# MCU_ECC_AGGR0_ECC_AGGR register map
Vendor: Texas Instruments
Peripheral module from a debugger description file (folder am243x).
Registers are 32-bit, access not given, reset 0x0 unless marked. A register's access mark holds for its fields unless they carry their own. Offsets are as the file gives them; lines under a group give offsets from that group; [hi:lo] are bit positions; {n}, {i} and the like mark numbered series; 'fields as' and 'values as' point back to an identical list; <NAME> marks a mode.

## MCU_ECC_AGGR0_ECC_AGGR
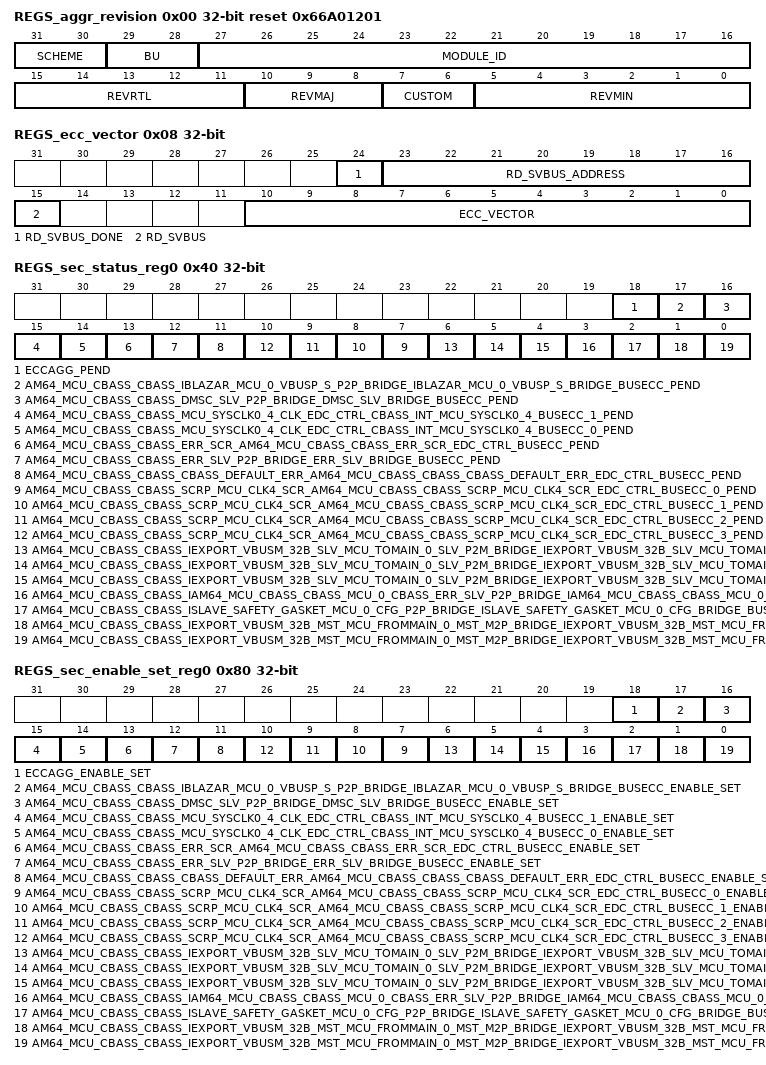
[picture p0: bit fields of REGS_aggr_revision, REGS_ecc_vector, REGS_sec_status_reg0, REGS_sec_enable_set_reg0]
0x00 REGS_aggr_revision ro reset 0x66A01201 — Revision parameters
  [31:30] SCHEME
  [29:28] BU
  [27:16] MODULE_ID
  [15:11] REVRTL — RTL version
  [10:8] REVMAJ — Major version
  [7:6] CUSTOM — Custom version
  [5:0] REVMIN — Minor version
0x08 REGS_ecc_vector — ECC Vector Register
  [24] RD_SVBUS_DONE — Status to indicate if read on serial VBUS is complete, write of any value will clear this bit. (access R/W1TC)
  [23:16] RD_SVBUS_ADDRESS rw — Read address
  [15] RD_SVBUS — Write 1 to trigger a read on the serial VBUS (access R/W1TS)
  [10:0] ECC_VECTOR rw — Value written to select the corresponding ECC RAM for control or status
0x0C REGS_misc_status ro reset 0x13 — Misc Status
  [10:0] NUM_RAMS — Indicates the number of RAMS serviced by the ECC aggregator
0x10 REGS_reserved_svbus rw — Reference other documents that contain the ECC RAM wrapper and EDC controller serial vbus register sets.
  [31:0] DATA — Serial VBUS register data
0x3C REGS_sec_eoi_reg — EOI Register
  [0] EOI_WR — EOI Register (access R/W1TS)
0x40 REGS_sec_status_reg0 — Interrupt Status Register 0
  [18] ECCAGG_PEND — Interrupt Pending Status for eccagg_pend (access R/W1TS)
  [17] AM64_MCU_CBASS_CBASS_IBLAZAR_MCU_0_VBUSP_S_P2P_BRIDGE_IBLAZAR_MCU_0_VBUSP_S_BRIDGE_BUSECC_PEND — Interrupt Pending Status for am64_mcu_cbass_cbass_Iblazar_mcu_0_vbusp_s_p2p_bridge_Iblazar_mcu_0_vbusp_s_bridge_busecc_pend (access R/W1TS)
  [16] AM64_MCU_CBASS_CBASS_DMSC_SLV_P2P_BRIDGE_DMSC_SLV_BRIDGE_BUSECC_PEND — Interrupt Pending Status for am64_mcu_cbass_cbass_dmsc_slv_p2p_bridge_dmsc_slv_bridge_busecc_pend (access R/W1TS)
  [15] AM64_MCU_CBASS_CBASS_MCU_SYSCLK0_4_CLK_EDC_CTRL_CBASS_INT_MCU_SYSCLK0_4_BUSECC_1_PEND — Interrupt Pending Status for am64_mcu_cbass_cbass_MCU_SYSCLK0_4_clk_edc_ctrl_cbass_int_MCU_SYSCLK0_4_busecc_1_pend (access R/W1TS)
  [14] AM64_MCU_CBASS_CBASS_MCU_SYSCLK0_4_CLK_EDC_CTRL_CBASS_INT_MCU_SYSCLK0_4_BUSECC_0_PEND — Interrupt Pending Status for am64_mcu_cbass_cbass_MCU_SYSCLK0_4_clk_edc_ctrl_cbass_int_MCU_SYSCLK0_4_busecc_0_pend (access R/W1TS)
  [13] AM64_MCU_CBASS_CBASS_ERR_SCR_AM64_MCU_CBASS_CBASS_ERR_SCR_EDC_CTRL_BUSECC_PEND — Interrupt Pending Status for am64_mcu_cbass_cbass_err_scr_am64_mcu_cbass_cbass_err_scr_edc_ctrl_busecc_pend (access R/W1TS)
  [12] AM64_MCU_CBASS_CBASS_ERR_SLV_P2P_BRIDGE_ERR_SLV_BRIDGE_BUSECC_PEND — Interrupt Pending Status for am64_mcu_cbass_cbass_err_slv_p2p_bridge_err_slv_bridge_busecc_pend (access R/W1TS)
  [11] AM64_MCU_CBASS_CBASS_CBASS_DEFAULT_ERR_AM64_MCU_CBASS_CBASS_CBASS_DEFAULT_ERR_EDC_CTRL_BUSECC_PEND — Interrupt Pending Status for am64_mcu_cbass_cbass_cbass_default_err_am64_mcu_cbass_cbass_cbass_default_err_edc_ctrl_busecc_pend (access R/W1TS)
  [n+7] AM64_MCU_CBASS_CBASS_SCRP_MCU_CLK4_SCR_AM64_MCU_CBASS_CBASS_SCRP_MCU_CLK4_SCR_EDC_CTRL_BUSECC_{n}_PEND (n=0..3) — Interrupt Pending Status for am64_mcu_cbass_cbass_scrp_mcu_clk4_scr_am64_mcu_cbass_cbass_scrp_mcu_clk4_scr_edc_ctrl_busecc_{n}_pend (access R/W1TS)
  [6] AM64_MCU_CBASS_CBASS_IEXPORT_VBUSM_32B_SLV_MCU_TOMAIN_0_SLV_P2M_BRIDGE_IEXPORT_VBUSM_32B_SLV_MCU_TOMAIN_0_SLV_BRIDGE_REASSEMBLY_BUSECC_PEND — Interrupt Pending Status for am64_mcu_cbass_cbass_Iexport_vbusm_32b_slv_mcu_tomain_0_slv_p2m_bridge_Iexport_vbusm_32b_slv_mcu_tomain_0_slv_bridge_reassembly_busecc_pend (access R/W1TS)
  [5] AM64_MCU_CBASS_CBASS_IEXPORT_VBUSM_32B_SLV_MCU_TOMAIN_0_SLV_P2M_BRIDGE_IEXPORT_VBUSM_32B_SLV_MCU_TOMAIN_0_SLV_BRIDGE_DST_BUSECC_PEND — Interrupt Pending Status for am64_mcu_cbass_cbass_Iexport_vbusm_32b_slv_mcu_tomain_0_slv_p2m_bridge_Iexport_vbusm_32b_slv_mcu_tomain_0_slv_bridge_dst_busecc_pend (access R/W1TS)
  [4] AM64_MCU_CBASS_CBASS_IEXPORT_VBUSM_32B_SLV_MCU_TOMAIN_0_SLV_P2M_BRIDGE_IEXPORT_VBUSM_32B_SLV_MCU_TOMAIN_0_SLV_BRIDGE_SRC_BUSECC_PEND — Interrupt Pending Status for am64_mcu_cbass_cbass_Iexport_vbusm_32b_slv_mcu_tomain_0_slv_p2m_bridge_Iexport_vbusm_32b_slv_mcu_tomain_0_slv_bridge_src_busecc_pend (access R/W1TS)
  [3] AM64_MCU_CBASS_CBASS_IAM64_MCU_CBASS_CBASS_MCU_0_CBASS_ERR_SLV_P2P_BRIDGE_IAM64_MCU_CBASS_CBASS_MCU_0_CBASS_ERR_SLV_BRIDGE_BUSECC_PEND — Interrupt Pending Status for am64_mcu_cbass_cbass_Iam64_mcu_cbass_cbass_mcu_0_cbass_err_slv_p2p_bridge_Iam64_mcu_cbass_cbass_mcu_0_cbass_err_slv_bridge_busecc_pend (access R/W1TS)
  [2] AM64_MCU_CBASS_CBASS_ISLAVE_SAFETY_GASKET_MCU_0_CFG_P2P_BRIDGE_ISLAVE_SAFETY_GASKET_MCU_0_CFG_BRIDGE_BUSECC_PEND — Interrupt Pending Status for am64_mcu_cbass_cbass_Islave_safety_gasket_mcu_0_cfg_p2p_bridge_Islave_safety_gasket_mcu_0_cfg_bridge_busecc_pend (access R/W1TS)
  [1] AM64_MCU_CBASS_CBASS_IEXPORT_VBUSM_32B_MST_MCU_FROMMAIN_0_MST_M2P_BRIDGE_IEXPORT_VBUSM_32B_MST_MCU_FROMMAIN_0_MST_BRIDGE_DST_BUSECC_PEND — Interrupt Pending Status for am64_mcu_cbass_cbass_Iexport_vbusm_32b_mst_mcu_frommain_0_mst_m2p_bridge_Iexport_vbusm_32b_mst_mcu_frommain_0_mst_bridge_dst_busecc_pend (access R/W1TS)
  [0] AM64_MCU_CBASS_CBASS_IEXPORT_VBUSM_32B_MST_MCU_FROMMAIN_0_MST_M2P_BRIDGE_IEXPORT_VBUSM_32B_MST_MCU_FROMMAIN_0_MST_BRIDGE_SRC_BUSECC_PEND — Interrupt Pending Status for am64_mcu_cbass_cbass_Iexport_vbusm_32b_mst_mcu_frommain_0_mst_m2p_bridge_Iexport_vbusm_32b_mst_mcu_frommain_0_mst_bridge_src_busecc_pend (access R/W1TS)
0x80 REGS_sec_enable_set_reg0 — Interrupt Enable Set Register 0
  [18] ECCAGG_ENABLE_SET — Interrupt Enable Set Register for eccagg_pend (access R/W1TS)
  [17] AM64_MCU_CBASS_CBASS_IBLAZAR_MCU_0_VBUSP_S_P2P_BRIDGE_IBLAZAR_MCU_0_VBUSP_S_BRIDGE_BUSECC_ENABLE_SET — Interrupt Enable Set Register for am64_mcu_cbass_cbass_Iblazar_mcu_0_vbusp_s_p2p_bridge_Iblazar_mcu_0_vbusp_s_bridge_busecc_pend (access R/W1TS)
  [16] AM64_MCU_CBASS_CBASS_DMSC_SLV_P2P_BRIDGE_DMSC_SLV_BRIDGE_BUSECC_ENABLE_SET — Interrupt Enable Set Register for am64_mcu_cbass_cbass_dmsc_slv_p2p_bridge_dmsc_slv_bridge_busecc_pend (access R/W1TS)
  [15] AM64_MCU_CBASS_CBASS_MCU_SYSCLK0_4_CLK_EDC_CTRL_CBASS_INT_MCU_SYSCLK0_4_BUSECC_1_ENABLE_SET — Interrupt Enable Set Register for am64_mcu_cbass_cbass_MCU_SYSCLK0_4_clk_edc_ctrl_cbass_int_MCU_SYSCLK0_4_busecc_1_pend (access R/W1TS)
  [14] AM64_MCU_CBASS_CBASS_MCU_SYSCLK0_4_CLK_EDC_CTRL_CBASS_INT_MCU_SYSCLK0_4_BUSECC_0_ENABLE_SET — Interrupt Enable Set Register for am64_mcu_cbass_cbass_MCU_SYSCLK0_4_clk_edc_ctrl_cbass_int_MCU_SYSCLK0_4_busecc_0_pend (access R/W1TS)
  [13] AM64_MCU_CBASS_CBASS_ERR_SCR_AM64_MCU_CBASS_CBASS_ERR_SCR_EDC_CTRL_BUSECC_ENABLE_SET — Interrupt Enable Set Register for am64_mcu_cbass_cbass_err_scr_am64_mcu_cbass_cbass_err_scr_edc_ctrl_busecc_pend (access R/W1TS)
  [12] AM64_MCU_CBASS_CBASS_ERR_SLV_P2P_BRIDGE_ERR_SLV_BRIDGE_BUSECC_ENABLE_SET — Interrupt Enable Set Register for am64_mcu_cbass_cbass_err_slv_p2p_bridge_err_slv_bridge_busecc_pend (access R/W1TS)
  [11] AM64_MCU_CBASS_CBASS_CBASS_DEFAULT_ERR_AM64_MCU_CBASS_CBASS_CBASS_DEFAULT_ERR_EDC_CTRL_BUSECC_ENABLE_SET — Interrupt Enable Set Register for am64_mcu_cbass_cbass_cbass_default_err_am64_mcu_cbass_cbass_cbass_default_err_edc_ctrl_busecc_pend (access R/W1TS)
  [n+7] AM64_MCU_CBASS_CBASS_SCRP_MCU_CLK4_SCR_AM64_MCU_CBASS_CBASS_SCRP_MCU_CLK4_SCR_EDC_CTRL_BUSECC_{n}_ENABLE_SET (n=0..3) — Interrupt Enable Set Register for am64_mcu_cbass_cbass_scrp_mcu_clk4_scr_am64_mcu_cbass_cbass_scrp_mcu_clk4_scr_edc_ctrl_busecc_{n}_pend (access R/W1TS)
  [6] AM64_MCU_CBASS_CBASS_IEXPORT_VBUSM_32B_SLV_MCU_TOMAIN_0_SLV_P2M_BRIDGE_IEXPORT_VBUSM_32B_SLV_MCU_TOMAIN_0_SLV_BRIDGE_REASSEMBLY_BUSECC_ENABLE_SET — Interrupt Enable Set Register for am64_mcu_cbass_cbass_Iexport_vbusm_32b_slv_mcu_tomain_0_slv_p2m_bridge_Iexport_vbusm_32b_slv_mcu_tomain_0_slv_bridge_reassembly_busecc_pend (access R/W1TS)
  [5] AM64_MCU_CBASS_CBASS_IEXPORT_VBUSM_32B_SLV_MCU_TOMAIN_0_SLV_P2M_BRIDGE_IEXPORT_VBUSM_32B_SLV_MCU_TOMAIN_0_SLV_BRIDGE_DST_BUSECC_ENABLE_SET — Interrupt Enable Set Register for am64_mcu_cbass_cbass_Iexport_vbusm_32b_slv_mcu_tomain_0_slv_p2m_bridge_Iexport_vbusm_32b_slv_mcu_tomain_0_slv_bridge_dst_busecc_pend (access R/W1TS)
  [4] AM64_MCU_CBASS_CBASS_IEXPORT_VBUSM_32B_SLV_MCU_TOMAIN_0_SLV_P2M_BRIDGE_IEXPORT_VBUSM_32B_SLV_MCU_TOMAIN_0_SLV_BRIDGE_SRC_BUSECC_ENABLE_SET — Interrupt Enable Set Register for am64_mcu_cbass_cbass_Iexport_vbusm_32b_slv_mcu_tomain_0_slv_p2m_bridge_Iexport_vbusm_32b_slv_mcu_tomain_0_slv_bridge_src_busecc_pend (access R/W1TS)
  [3] AM64_MCU_CBASS_CBASS_IAM64_MCU_CBASS_CBASS_MCU_0_CBASS_ERR_SLV_P2P_BRIDGE_IAM64_MCU_CBASS_CBASS_MCU_0_CBASS_ERR_SLV_BRIDGE_BUSECC_ENABLE_SET — Interrupt Enable Set Register for am64_mcu_cbass_cbass_Iam64_mcu_cbass_cbass_mcu_0_cbass_err_slv_p2p_bridge_Iam64_mcu_cbass_cbass_mcu_0_cbass_err_slv_bridge_busecc_pend (access R/W1TS)
  [2] AM64_MCU_CBASS_CBASS_ISLAVE_SAFETY_GASKET_MCU_0_CFG_P2P_BRIDGE_ISLAVE_SAFETY_GASKET_MCU_0_CFG_BRIDGE_BUSECC_ENABLE_SET — Interrupt Enable Set Register for am64_mcu_cbass_cbass_Islave_safety_gasket_mcu_0_cfg_p2p_bridge_Islave_safety_gasket_mcu_0_cfg_bridge_busecc_pend (access R/W1TS)
  [1] AM64_MCU_CBASS_CBASS_IEXPORT_VBUSM_32B_MST_MCU_FROMMAIN_0_MST_M2P_BRIDGE_IEXPORT_VBUSM_32B_MST_MCU_FROMMAIN_0_MST_BRIDGE_DST_BUSECC_ENABLE_SET — Interrupt Enable Set Register for am64_mcu_cbass_cbass_Iexport_vbusm_32b_mst_mcu_frommain_0_mst_m2p_bridge_Iexport_vbusm_32b_mst_mcu_frommain_0_mst_bridge_dst_busecc_pend (access R/W1TS)
  [0] AM64_MCU_CBASS_CBASS_IEXPORT_VBUSM_32B_MST_MCU_FROMMAIN_0_MST_M2P_BRIDGE_IEXPORT_VBUSM_32B_MST_MCU_FROMMAIN_0_MST_BRIDGE_SRC_BUSECC_ENABLE_SET — Interrupt Enable Set Register for am64_mcu_cbass_cbass_Iexport_vbusm_32b_mst_mcu_frommain_0_mst_m2p_bridge_Iexport_vbusm_32b_mst_mcu_frommain_0_mst_bridge_src_busecc_pend (access R/W1TS)
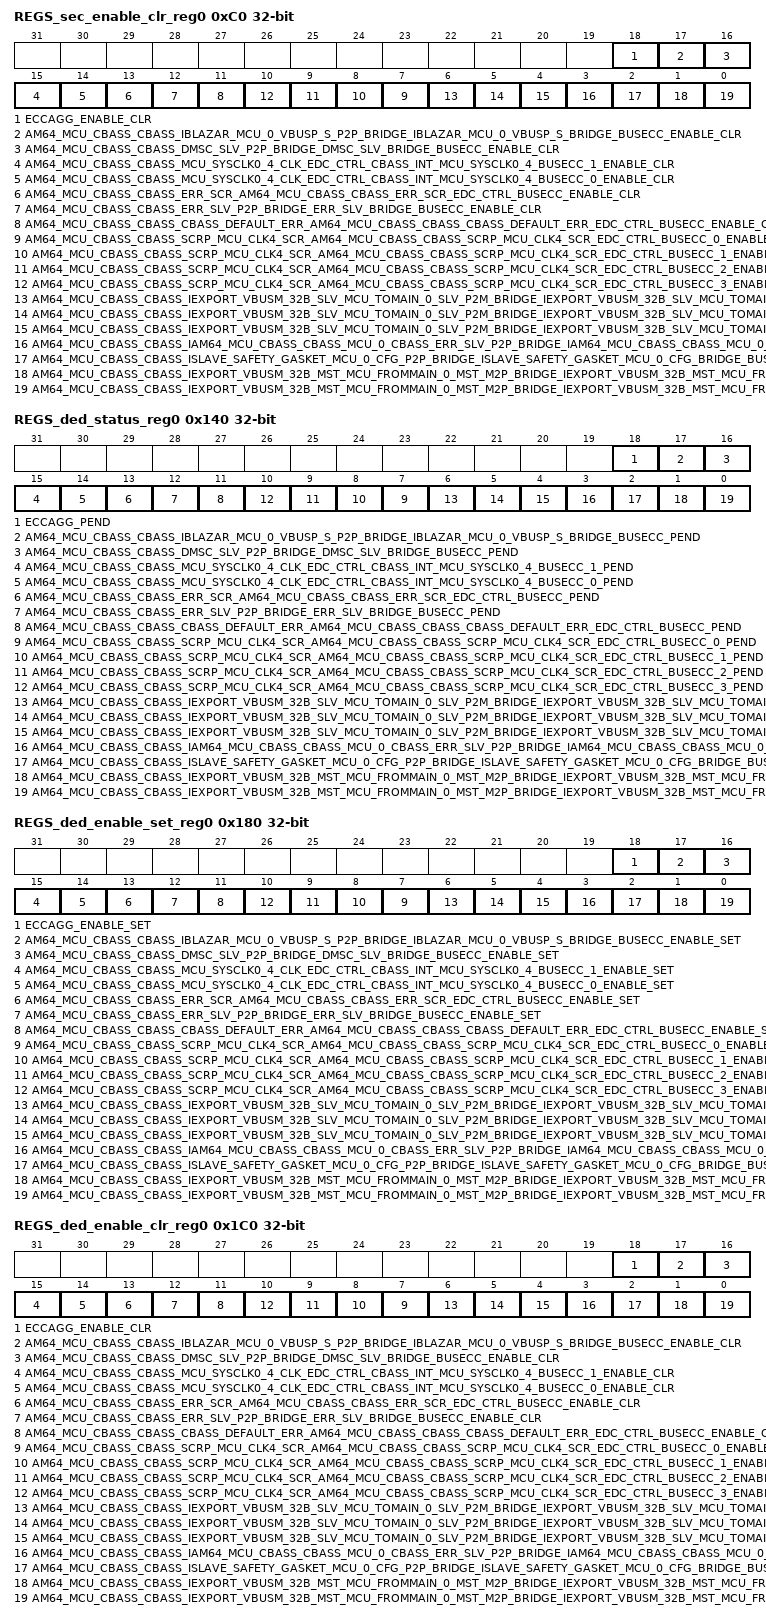
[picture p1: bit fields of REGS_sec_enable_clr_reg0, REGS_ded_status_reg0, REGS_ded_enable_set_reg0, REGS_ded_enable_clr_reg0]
0xC0 REGS_sec_enable_clr_reg0 — Interrupt Enable Clear Register 0
  [18] ECCAGG_ENABLE_CLR — Interrupt Enable Clear Register for eccagg_pend (access R/W1TC)
  [17] AM64_MCU_CBASS_CBASS_IBLAZAR_MCU_0_VBUSP_S_P2P_BRIDGE_IBLAZAR_MCU_0_VBUSP_S_BRIDGE_BUSECC_ENABLE_CLR — Interrupt Enable Clear Register for am64_mcu_cbass_cbass_Iblazar_mcu_0_vbusp_s_p2p_bridge_Iblazar_mcu_0_vbusp_s_bridge_busecc_pend (access R/W1TC)
  [16] AM64_MCU_CBASS_CBASS_DMSC_SLV_P2P_BRIDGE_DMSC_SLV_BRIDGE_BUSECC_ENABLE_CLR — Interrupt Enable Clear Register for am64_mcu_cbass_cbass_dmsc_slv_p2p_bridge_dmsc_slv_bridge_busecc_pend (access R/W1TC)
  [15] AM64_MCU_CBASS_CBASS_MCU_SYSCLK0_4_CLK_EDC_CTRL_CBASS_INT_MCU_SYSCLK0_4_BUSECC_1_ENABLE_CLR — Interrupt Enable Clear Register for am64_mcu_cbass_cbass_MCU_SYSCLK0_4_clk_edc_ctrl_cbass_int_MCU_SYSCLK0_4_busecc_1_pend (access R/W1TC)
  [14] AM64_MCU_CBASS_CBASS_MCU_SYSCLK0_4_CLK_EDC_CTRL_CBASS_INT_MCU_SYSCLK0_4_BUSECC_0_ENABLE_CLR — Interrupt Enable Clear Register for am64_mcu_cbass_cbass_MCU_SYSCLK0_4_clk_edc_ctrl_cbass_int_MCU_SYSCLK0_4_busecc_0_pend (access R/W1TC)
  [13] AM64_MCU_CBASS_CBASS_ERR_SCR_AM64_MCU_CBASS_CBASS_ERR_SCR_EDC_CTRL_BUSECC_ENABLE_CLR — Interrupt Enable Clear Register for am64_mcu_cbass_cbass_err_scr_am64_mcu_cbass_cbass_err_scr_edc_ctrl_busecc_pend (access R/W1TC)
  [12] AM64_MCU_CBASS_CBASS_ERR_SLV_P2P_BRIDGE_ERR_SLV_BRIDGE_BUSECC_ENABLE_CLR — Interrupt Enable Clear Register for am64_mcu_cbass_cbass_err_slv_p2p_bridge_err_slv_bridge_busecc_pend (access R/W1TC)
  [11] AM64_MCU_CBASS_CBASS_CBASS_DEFAULT_ERR_AM64_MCU_CBASS_CBASS_CBASS_DEFAULT_ERR_EDC_CTRL_BUSECC_ENABLE_CLR — Interrupt Enable Clear Register for am64_mcu_cbass_cbass_cbass_default_err_am64_mcu_cbass_cbass_cbass_default_err_edc_ctrl_busecc_pend (access R/W1TC)
  [n+7] AM64_MCU_CBASS_CBASS_SCRP_MCU_CLK4_SCR_AM64_MCU_CBASS_CBASS_SCRP_MCU_CLK4_SCR_EDC_CTRL_BUSECC_{n}_ENABLE_CLR (n=0..3) — Interrupt Enable Clear Register for am64_mcu_cbass_cbass_scrp_mcu_clk4_scr_am64_mcu_cbass_cbass_scrp_mcu_clk4_scr_edc_ctrl_busecc_{n}_pend (access R/W1TC)
  [6] AM64_MCU_CBASS_CBASS_IEXPORT_VBUSM_32B_SLV_MCU_TOMAIN_0_SLV_P2M_BRIDGE_IEXPORT_VBUSM_32B_SLV_MCU_TOMAIN_0_SLV_BRIDGE_REASSEMBLY_BUSECC_ENABLE_CLR — Interrupt Enable Clear Register for am64_mcu_cbass_cbass_Iexport_vbusm_32b_slv_mcu_tomain_0_slv_p2m_bridge_Iexport_vbusm_32b_slv_mcu_tomain_0_slv_bridge_reassembly_busecc_pend (access R/W1TC)
  [5] AM64_MCU_CBASS_CBASS_IEXPORT_VBUSM_32B_SLV_MCU_TOMAIN_0_SLV_P2M_BRIDGE_IEXPORT_VBUSM_32B_SLV_MCU_TOMAIN_0_SLV_BRIDGE_DST_BUSECC_ENABLE_CLR — Interrupt Enable Clear Register for am64_mcu_cbass_cbass_Iexport_vbusm_32b_slv_mcu_tomain_0_slv_p2m_bridge_Iexport_vbusm_32b_slv_mcu_tomain_0_slv_bridge_dst_busecc_pend (access R/W1TC)
  [4] AM64_MCU_CBASS_CBASS_IEXPORT_VBUSM_32B_SLV_MCU_TOMAIN_0_SLV_P2M_BRIDGE_IEXPORT_VBUSM_32B_SLV_MCU_TOMAIN_0_SLV_BRIDGE_SRC_BUSECC_ENABLE_CLR — Interrupt Enable Clear Register for am64_mcu_cbass_cbass_Iexport_vbusm_32b_slv_mcu_tomain_0_slv_p2m_bridge_Iexport_vbusm_32b_slv_mcu_tomain_0_slv_bridge_src_busecc_pend (access R/W1TC)
  [3] AM64_MCU_CBASS_CBASS_IAM64_MCU_CBASS_CBASS_MCU_0_CBASS_ERR_SLV_P2P_BRIDGE_IAM64_MCU_CBASS_CBASS_MCU_0_CBASS_ERR_SLV_BRIDGE_BUSECC_ENABLE_CLR — Interrupt Enable Clear Register for am64_mcu_cbass_cbass_Iam64_mcu_cbass_cbass_mcu_0_cbass_err_slv_p2p_bridge_Iam64_mcu_cbass_cbass_mcu_0_cbass_err_slv_bridge_busecc_pend (access R/W1TC)
  [2] AM64_MCU_CBASS_CBASS_ISLAVE_SAFETY_GASKET_MCU_0_CFG_P2P_BRIDGE_ISLAVE_SAFETY_GASKET_MCU_0_CFG_BRIDGE_BUSECC_ENABLE_CLR — Interrupt Enable Clear Register for am64_mcu_cbass_cbass_Islave_safety_gasket_mcu_0_cfg_p2p_bridge_Islave_safety_gasket_mcu_0_cfg_bridge_busecc_pend (access R/W1TC)
  [1] AM64_MCU_CBASS_CBASS_IEXPORT_VBUSM_32B_MST_MCU_FROMMAIN_0_MST_M2P_BRIDGE_IEXPORT_VBUSM_32B_MST_MCU_FROMMAIN_0_MST_BRIDGE_DST_BUSECC_ENABLE_CLR — Interrupt Enable Clear Register for am64_mcu_cbass_cbass_Iexport_vbusm_32b_mst_mcu_frommain_0_mst_m2p_bridge_Iexport_vbusm_32b_mst_mcu_frommain_0_mst_bridge_dst_busecc_pend (access R/W1TC)
  [0] AM64_MCU_CBASS_CBASS_IEXPORT_VBUSM_32B_MST_MCU_FROMMAIN_0_MST_M2P_BRIDGE_IEXPORT_VBUSM_32B_MST_MCU_FROMMAIN_0_MST_BRIDGE_SRC_BUSECC_ENABLE_CLR — Interrupt Enable Clear Register for am64_mcu_cbass_cbass_Iexport_vbusm_32b_mst_mcu_frommain_0_mst_m2p_bridge_Iexport_vbusm_32b_mst_mcu_frommain_0_mst_bridge_src_busecc_pend (access R/W1TC)
0x13C REGS_ded_eoi_reg — EOI Register
  [0] EOI_WR — EOI Register (access R/W1TS)
0x140 REGS_ded_status_reg0 — Interrupt Status Register 0
  fields as REGS_sec_status_reg0
0x180 REGS_ded_enable_set_reg0 — Interrupt Enable Set Register 0
  fields as REGS_sec_enable_set_reg0
0x1C0 REGS_ded_enable_clr_reg0 — Interrupt Enable Clear Register 0
  fields as REGS_sec_enable_clr_reg0
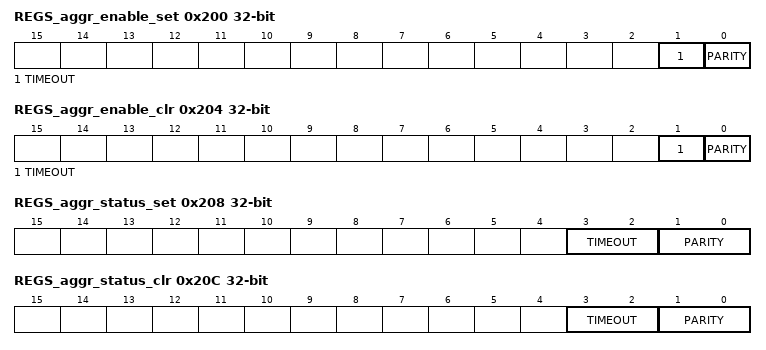
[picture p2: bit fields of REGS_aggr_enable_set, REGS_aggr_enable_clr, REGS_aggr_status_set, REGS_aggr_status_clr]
0x200 REGS_aggr_enable_set — AGGR interrupt enable set Register
  [1] TIMEOUT — interrupt enable set for svbus timeout errors (access R/W1TS)
  [0] PARITY — interrupt enable set for parity errors (access R/W1TS)
0x204 REGS_aggr_enable_clr — AGGR interrupt enable clear Register
  [1] TIMEOUT — interrupt enable clear for svbus timeout errors (access R/W1TC)
  [0] PARITY — interrupt enable clear for parity errors (access R/W1TC)
0x208 REGS_aggr_status_set — AGGR interrupt status set Register
  [3:2] TIMEOUT — interrupt status set for svbus timeout errors (access R/WI)
  [1:0] PARITY — interrupt status set for parity errors (access R/WI)
0x20C REGS_aggr_status_clr — AGGR interrupt status clear Register
  [3:2] TIMEOUT — interrupt status clear for svbus timeout errors (access R/WD)
  [1:0] PARITY — interrupt status clear for parity errors (access R/WD)
